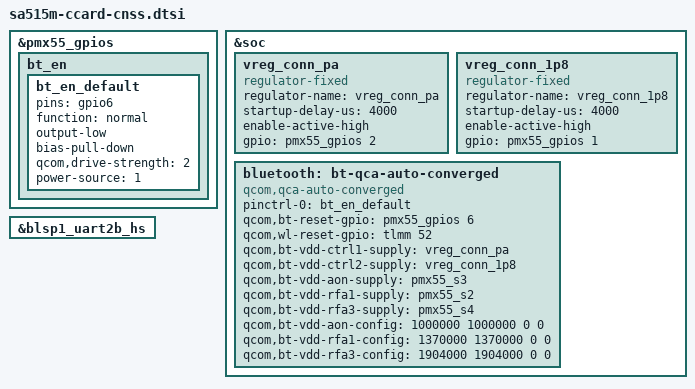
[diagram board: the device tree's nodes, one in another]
#include "pmx55.dtsi"
#include <dt-bindings/pinctrl/qcom,pmic-gpio.h>

&pmx55_gpios {

	bt_en {
		bt_en_default: bt_en_default {
			pins = "gpio6";
			function = "normal";
			output-low;
			bias-pull-down;
			qcom,drive-strength = <2>;
			power-source = <1>;
		};
	};
};

&soc {

	vreg_conn_pa: vreg_conn_pa {
		compatible = "regulator-fixed";
		regulator-name = "vreg_conn_pa";
		startup-delay-us = <4000>;
		enable-active-high;
		gpio = <&pmx55_gpios 2 GPIO_ACTIVE_HIGH>;
	};

	vreg_conn_1p8: vreg_conn_1p8 {
		compatible = "regulator-fixed";
		regulator-name = "vreg_conn_1p8";
		startup-delay-us = <4000>;
		enable-active-high;
		gpio = <&pmx55_gpios 1 GPIO_ACTIVE_HIGH>;
	};

	bluetooth: bt-qca-auto-converged {
		compatible = "qcom,qca-auto-converged";
		pinctrl-names = "default";
		pinctrl-0 = <&bt_en_default>;
		qcom,bt-reset-gpio = <&pmx55_gpios 6 0>;
		qcom,wl-reset-gpio = <&tlmm 52 0>;

		qcom,bt-vdd-ctrl1-supply = <&vreg_conn_pa>;
		qcom,bt-vdd-ctrl2-supply = <&vreg_conn_1p8>;
		qcom,bt-vdd-aon-supply  = <&pmx55_s3>;
		qcom,bt-vdd-rfa1-supply = <&pmx55_s2>;
		qcom,bt-vdd-rfa3-supply = <&pmx55_s4>;

		qcom,bt-vdd-aon-config  = <1000000 1000000 0 0>;
		qcom,bt-vdd-rfa1-config = <1370000 1370000 0 0>;
		qcom,bt-vdd-rfa3-config = <1904000 1904000 0 0>;
	};
};

&blsp1_uart2b_hs {
	status = "okay";
};
